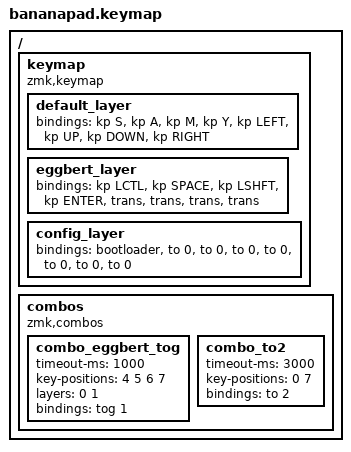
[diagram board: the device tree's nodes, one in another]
/*
 * Copyright (c) 2020 The ZMK Contributors
 *
 * SPDX-License-Identifier: MIT
 */

#include <behaviors.dtsi>
#include <dt-bindings/zmk/keys.h>

/ {
    keymap {
        compatible = "zmk,keymap";

        default_layer {
            bindings = <
            &kp S &kp A &kp M &kp Y &kp LEFT &kp UP &kp DOWN &kp RIGHT
            >;
        };

        eggbert_layer {
            bindings = <
            &kp LCTL &kp SPACE &kp LSHFT &kp ENTER &trans &trans &trans &trans
            >;
        };

        config_layer {
            bindings = <
            &bootloader &to 0 &to 0 &to 0 &to 0 &to 0 &to 0 &to 0
            >;
        };
    };

    combos {
        compatible = "zmk,combos";
        combo_eggbert_tog {
            timeout-ms = <1000>;
            key-positions = <4 5 6 7>;
            layers = <0 1>;
            bindings = <&tog 1>;
        };
        combo_to2 {
            timeout-ms = <3000>;
            key-positions = <0 7>;
            bindings = <&to 2>;
        };
    };
};
